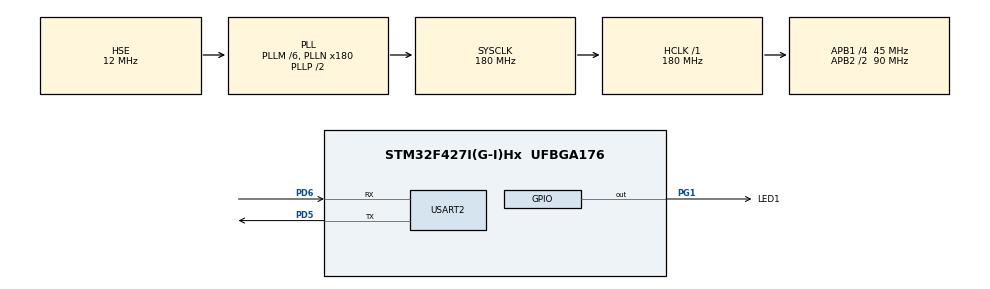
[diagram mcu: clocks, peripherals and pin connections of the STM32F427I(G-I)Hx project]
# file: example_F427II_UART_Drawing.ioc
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Dma.Request0=USART2_RX
Dma.Request1=USART2_TX
Dma.USART2_RX.0.Direction=DMA_PERIPH_TO_MEMORY
Dma.USART2_RX.0.FIFOMode=DMA_FIFOMODE_DISABLE
Dma.USART2_RX.0.Instance=DMA1_Stream5
Dma.USART2_RX.0.MemDataAlignment=DMA_MDATAALIGN_BYTE
Dma.USART2_RX.0.MemInc=DMA_MINC_ENABLE
Dma.USART2_RX.0.Mode=DMA_NORMAL
Dma.USART2_RX.0.PeriphDataAlignment=DMA_PDATAALIGN_BYTE
Dma.USART2_RX.0.PeriphInc=DMA_PINC_DISABLE
Dma.USART2_RX.0.Priority=DMA_PRIORITY_LOW
Dma.USART2_TX.1.Direction=DMA_MEMORY_TO_PERIPH
Dma.USART2_TX.1.FIFOMode=DMA_FIFOMODE_DISABLE
Dma.USART2_TX.1.Instance=DMA1_Stream6
Dma.USART2_TX.1.MemDataAlignment=DMA_MDATAALIGN_BYTE
Dma.USART2_TX.1.MemInc=DMA_MINC_ENABLE
Dma.USART2_TX.1.Mode=DMA_NORMAL
Dma.USART2_TX.1.PeriphDataAlignment=DMA_PDATAALIGN_BYTE
Dma.USART2_TX.1.PeriphInc=DMA_PINC_DISABLE
Dma.USART2_TX.1.Priority=DMA_PRIORITY_LOW
Mcu.Family=STM32F4
Mcu.Name=STM32F427I(G-I)Hx
Mcu.Package=UFBGA176
NVIC.DMA1_Stream5_IRQn=true\:0\:0\:false\:false\:true\:false\:true\:true
NVIC.DMA1_Stream6_IRQn=true\:0\:0\:false\:false\:true\:false\:true\:true
NVIC.PriorityGroup=NVIC_PRIORITYGROUP_4
NVIC.USART2_IRQn=true\:0\:0\:false\:false\:true\:false\:true\:true
PA13.Mode=Serial_Wire
PA13.Signal=SYS_JTMS-SWDIO
PA14.Mode=Serial_Wire
PA14.Signal=SYS_JTCK-SWCLK
PD5.Mode=Asynchronous
PD5.Signal=USART2_TX
PD6.Mode=Asynchronous
PD6.Signal=USART2_RX
PG1.GPIO_Label=LED1
PG1.PinState=GPIO_PIN_SET
PG1.Signal=GPIO_Output
PH0/OSC_IN.Mode=HSE-External-Oscillator
PH0/OSC_IN.Signal=RCC_OSC_IN
PH1/OSC_OUT.Mode=HSE-External-Oscillator
PH1/OSC_OUT.Signal=RCC_OSC_OUT
ProjectManager.HeapSize=0x200
ProjectManager.StackSize=0x400
ProjectManager.TargetToolchain=CMake
RCC.48MHZClocksFreq_Value=90000000
RCC.AHBFreq_Value=180000000
RCC.APB1CLKDivider=RCC_HCLK_DIV4
RCC.APB1Freq_Value=45000000
RCC.APB1TimFreq_Value=90000000
RCC.APB2CLKDivider=RCC_HCLK_DIV2
RCC.APB2Freq_Value=90000000
RCC.APB2TimFreq_Value=180000000
RCC.CortexFreq_Value=180000000
RCC.HCLKFreq_Value=180000000
RCC.HSE_VALUE=12000000
RCC.HSI_VALUE=16000000
RCC.LSE_VALUE=32768
RCC.PLLM=6
RCC.PLLN=180
RCC.PLLSourceVirtual=RCC_PLLSOURCE_HSE
RCC.SYSCLKFreq_VALUE=180000000
RCC.SYSCLKSource=RCC_SYSCLKSOURCE_PLLCLK
RCC.VCOOutputFreq_Value=360000000
USART2.VirtualMode=VM_ASYNC
board=custom

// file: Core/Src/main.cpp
/* USER CODE BEGIN Header */
/**
  ******************************************************************************
  * @file           : main.c
  * @brief          : Main program body
  ******************************************************************************
  * @attention
  *
  * Copyright (c) 2026 STMicroelectronics.
  * All rights reserved.
  *
  * This software is licensed under terms that can be found in the LICENSE file
  * in the root directory of this software component.
  * If no LICENSE file comes with this software, it is provided AS-IS.
  *
  ******************************************************************************
  */
/* USER CODE END Header */
#include "main.h"
#include "dma.h"
#include "usart.h"
#include "gpio.h"

/* USER CODE BEGIN Includes */
#include "drv_bsp.h"
#include "drv_uart.h"
/* USER CODE END Includes */

/* USER CODE BEGIN PV */
uint8_t tx_buffer[9] = {0xAB};
uint8_t rx_buffer[10];
/* USER CODE END PV */

void SystemClock_Config(void);
/* USER CODE BEGIN PFP */
/**
 * @brief HAL 库 UART 接收 DMA 空闲中断
 * @param Buffer UART编号
 * @param Length 长度
 */
void Serialplot_Call_Back(uint8_t *Buffer, uint16_t Length)
{
  if (rx_buffer[0] == '0')
  {
    BSP_LED_1(BSP_LED_Status_DISABLED);
  }
  else if (rx_buffer[0] == '1')
  {
    BSP_LED_1(BSP_LED_Status_ENABLED);
  }
  else if (rx_buffer[0] == '2')
  {
    HAL_GPIO_TogglePin(LED1_GPIO_Port, LED1_Pin);
  }
}
/* USER CODE END PFP */

int main(void)
{

  /* MCU Configuration--------------------------------------------------------*/

  /* Reset of all peripherals, Initializes the Flash interface and the Systick. */
  HAL_Init();

  /* Configure the system clock */
  SystemClock_Config();

  /* Initialize all configured peripherals */
  MX_GPIO_Init();
  MX_DMA_Init();
  MX_USART2_UART_Init();
  /* USER CODE BEGIN 2 */
  Uart_Init(&huart2, rx_buffer, 10, Serialplot_Call_Back);
  /* USER CODE END 2 */

  /* Infinite loop */
  /* USER CODE BEGIN WHILE */
  while (1)
  {
    static uint32_t flag;
    if (flag == 2500)
    {
      flag = 0;
    }
    float tmp_data;
    tmp_data = ((float)flag / 1000.0f) * ((float)flag / 1000.0f);
    for (uint8_t i = 0; i < 4; i++)
    {
      tx_buffer[i + 1] = *((char *)(&tmp_data) + i);
    }

    float led_status;
    led_status = !HAL_GPIO_ReadPin(LED1_GPIO_Port, LED1_Pin);
    for (uint8_t i = 0; i < 4; i++)
    {
      tx_buffer[i + 5] = *((char *)(&led_status) + i);
    }

    HAL_Delay(0);
    flag++;
    UART_Send_Data(&huart2, tx_buffer, 9);
    /* USER CODE END WHILE */

  }
}

void SystemClock_Config(void)
{
  RCC_OscInitTypeDef RCC_OscInitStruct = {0};
  RCC_ClkInitTypeDef RCC_ClkInitStruct = {0};

  /** Configure the main internal regulator output voltage
  */
  __HAL_RCC_PWR_CLK_ENABLE();
  __HAL_PWR_VOLTAGESCALING_CONFIG(PWR_REGULATOR_VOLTAGE_SCALE1);

  /** Initializes the RCC Oscillators according to the specified parameters
  * in the RCC_OscInitTypeDef structure.
  */
  RCC_OscInitStruct.OscillatorType = RCC_OSCILLATORTYPE_HSE;
  RCC_OscInitStruct.HSEState = RCC_HSE_ON;
  RCC_OscInitStruct.PLL.PLLState = RCC_PLL_ON;
  RCC_OscInitStruct.PLL.PLLSource = RCC_PLLSOURCE_HSE;
  RCC_OscInitStruct.PLL.PLLM = 6;
  RCC_OscInitStruct.PLL.PLLN = 180;
  RCC_OscInitStruct.PLL.PLLP = RCC_PLLP_DIV2;
  RCC_OscInitStruct.PLL.PLLQ = 4;
  if (HAL_RCC_OscConfig(&RCC_OscInitStruct) != HAL_OK)
  {
    Error_Handler();
  }

  /** Activate the Over-Drive mode
  */
  if (HAL_PWREx_EnableOverDrive() != HAL_OK)
  {
    Error_Handler();
  }

  /** Initializes the CPU, AHB and APB buses clocks
  */
  RCC_ClkInitStruct.ClockType = RCC_CLOCKTYPE_HCLK|RCC_CLOCKTYPE_SYSCLK
                              |RCC_CLOCKTYPE_PCLK1|RCC_CLOCKTYPE_PCLK2;
  RCC_ClkInitStruct.SYSCLKSource = RCC_SYSCLKSOURCE_PLLCLK;
  RCC_ClkInitStruct.AHBCLKDivider = RCC_SYSCLK_DIV1;
  RCC_ClkInitStruct.APB1CLKDivider = RCC_HCLK_DIV4;
  RCC_ClkInitStruct.APB2CLKDivider = RCC_HCLK_DIV2;

  if (HAL_RCC_ClockConfig(&RCC_ClkInitStruct, FLASH_LATENCY_5) != HAL_OK)
  {
    Error_Handler();
  }
}

void Error_Handler(void)
{
  __disable_irq();
  while (1)
  {
  }
}
